# DSS_DSS_COMMON1_30201000h register map
Vendor: Texas Instruments
Peripheral module from a debugger description file (folder am62L).
Registers are 32-bit, access not given, reset 0x0 unless marked. A register's access mark holds for its fields unless they carry their own. Offsets are as the file gives them; lines under a group give offsets from that group; [hi:lo] are bit positions; {n}, {i} and the like mark numbered series; 'fields as' and 'values as' point back to an identical list; <NAME> marks a mode.

## DSS_COMMON1
0x24 DSS_COMMON1_DISPC_IRQ_EOI wo — End Of Interrupt number
  [0] EOI — Software End Of Interrupt [EOI] control if pulse interrupts are used. Write 1 to acknowledge interrupt 0 Write-0 : No action1 Write-1 : End-of-Interrupt
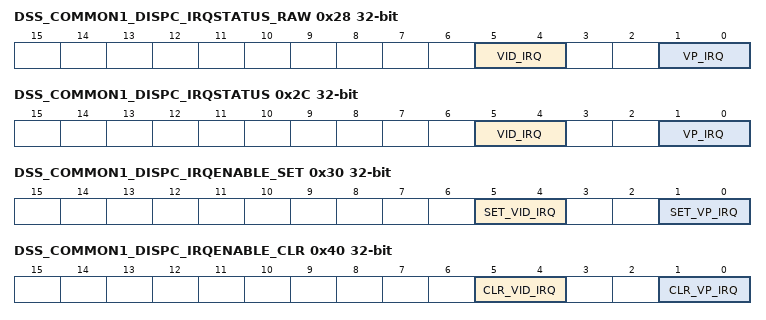
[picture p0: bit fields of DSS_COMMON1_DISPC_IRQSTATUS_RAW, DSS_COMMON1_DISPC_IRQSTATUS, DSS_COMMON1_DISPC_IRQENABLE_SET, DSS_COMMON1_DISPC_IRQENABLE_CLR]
0x28 DSS_COMMON1_DISPC_IRQSTATUS_RAW — RAW Interrupt status. Raw status is set even if interrupt is not enabled. Write 1 to set the RAW status
  [5:4] VID_IRQ — Bit[4]: Reserved, Should be written with 0; Bit[5]:Register indicates the VIDL1 interrupt events ; 0 Write-0 : No action, Read-0 : No event pending1 Write-1 : Set event, Read-1 : IRQ event pending (access R/W1TS)
  [1:0] VP_IRQ — Bit[0]: VP1 IRQ STATUS; Bit[1]: Reserved, Should be written with 0; 0 Write-0 : No action, Read-0 : No event pending1 Write-1 : Set event, Read-1 : IRQ event pending (access R/W1TS)
0x2C DSS_COMMON1_DISPC_IRQSTATUS — Interrupt status. Enabled status, isn't set unless event is enabled. Write 1 to clear the status after interrupt has been serviced. RAW status also gets cleared, i.e. even if not enabled
  [5:4] VID_IRQ — Bit[4]: Reserved, Should be written with 0; Bit[5]:VIDL1 IRQ STATUS; 0 Write-0 : No action, Read-0 : No event pending1 Write-1 : Clear pending event, if any, Read-1 : IRQ event pending (access R/W1TC)
  [1:0] VP_IRQ — Bit[0]: VP1 IRQ STATUS; Bit[1]: Reserved, Should be written with 0; 0 Write-0 : No action, Read-0 : No event pending1 Write-1 : Clear pending event, if any, Read-1 : IRQ event pending (access R/W1TC)
0x30 DSS_COMMON1_DISPC_IRQENABLE_SET — SET Interrupt enable. Write 1 to set interrupt enable. Readout equal to corresponding _CLR register
  [5:4] SET_VID_IRQ — Bit[4]: Reserved, Should be written with 0; Bit[5]:VIDL1 IRQ ; 0 Write-0 : No action, Read-0 : Interrupt Disabled1 Write-1 : Enable interrupt, Read-1 : Interrupt Enabled (access R/W1TS)
  [1:0] SET_VP_IRQ — Bit[0]: VP1 IRQ ; Bit[1]: Reserved, Should be written with 0; 0 Write-0 : No action, Read-0 : Interrupt Disabled1 Write-1 : Enable interrupt, Read-1 : Interrupt Enabled (access R/W1TS)
0x40 DSS_COMMON1_DISPC_IRQENABLE_CLR — CLR Interrupt enable. Write 1 to clear interrupt enable
  [5:4] CLR_VID_IRQ — Bit[4]: Reserved, Should be written with 0; Bit[5]:VIDL1 IRQ ; 0 Write-0 : No action, Read-0 : Interrupt Disabled1 Write-1 : Clear interrupt, Read-1 : Interrupt Enabled (access R/W1TC)
  [1:0] CLR_VP_IRQ — Bit[0]: VP1 IRQ ; Bit[1]: Reserved, Should be written with 0; 0 Write-0 : No action, Read-0 : Interrupt Disabled1 Write-1 : Clear interrupt, Read-1 : Interrupt Enabled (access R/W1TC)
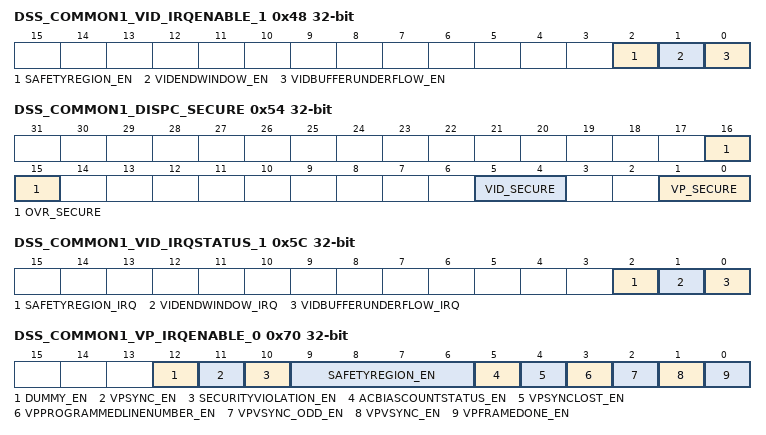
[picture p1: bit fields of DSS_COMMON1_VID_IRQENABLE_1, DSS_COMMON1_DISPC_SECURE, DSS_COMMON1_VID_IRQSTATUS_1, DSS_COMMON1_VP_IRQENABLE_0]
0x48 DSS_COMMON1_VID_IRQENABLE_1 rw — This register allows to mask/unmask the VIDL1 internal sources of interrupt, on an event-by-event basis
  [2] SAFETYREGION_EN — Safety Feature IRQ. This is raised when FrameFreeze is detected or data mismatch occurs within the safety region 0 Event is masked1 Event generates an interrupt when it occurs
  [1] VIDENDWINDOW_EN — Video End Window. This is raised by the DMA engine when the full video data has been sent to the pipeline 0 Event is masked1 Event generates an interrupt when it occurs
  [0] VIDBUFFERUNDERFLOW_EN — Video DMA Buffer Underflow. This is raised when the DMA buffer does not have the data requested by the Video pipeline 0 Event is masked1 Event generates an interrupt when it occurs
0x54 DSS_COMMON1_DISPC_SECURE rw — Security bit settings for different DISPC sub-modules
  [16:15] OVR_SECURE — Secure bit for OVR 0 Secure bit is reset1 Secure bit is set
  [5:4] VID_SECURE — Bit[4]: Reserved , Should be written 0; Bit[5]:Secure bit for VIDL1; 0 Secure bit is reset1 Secure bit is set
  [1:0] VP_SECURE — Bit[0]:Secure bit for VP1; Bit[1]:Reserved, Should be written with 0; 0 Secure bit is reset1 Secure bit is set
0x5C DSS_COMMON1_VID_IRQSTATUS_1 — This register groups all the status of the VIDL1 internal events that generate an interrupt. Write 1 to a clear a bit field
  [2] SAFETYREGION_IRQ — Safety Feature IRQ. This is raised when FrameFreeze is detected or data mismatch occurs within the safety region 0 Write: Status is unchanged, Read: Event is not pending1 Write: Status is reset, Read: Event is Pending (access R/W1TC)
  [1] VIDENDWINDOW_IRQ — Video End Window. This is raised by the DMA engine when the full video data has been sent to the pipeline 0 Write: Status is unchanged, Read: Event is not pending1 Write: Status is reset, Read: Event is Pending (access R/W1TC)
  [0] VIDBUFFERUNDERFLOW_IRQ — Video DMA Buffer Underflow. This is raised when the DMA buffer does not have the data requested by the Video pipeline 0 Write: Status is unchanged, Read: Event is not pending1 Write: Status is reset, Read: Event is Pending (access R/W1TC)
0x70 DSS_COMMON1_VP_IRQENABLE_0 rw — This register allows to mask/unmask the VP_1 internal sources of interrupt, on an event-by-event basis
  [12] DUMMY_EN — Dummy IRQ for future use, in DSS_nano it should always be masked 0 Event is masked1 Event generates an interrupt when it occurs
  [11] VPSYNC_EN — Go bit clear event 0 Event is masked1 Event generates an interrupt when it occurs
  [10] SECURITYVIOLATION_EN — Security Violation interrupt for OVR/VP1. Non-secure OVR/VP1 connected to secure VID 0 Event is masked1 Event generates an interrupt when it occurs
  [9:6] SAFETYREGION_EN — Safety Feature IRQ. This is raised when FrameFreeze is detected or data mismatch occurs within the safety region 0 Event is masked1 Event generates an interrupt when it occurs
  [5] ACBIASCOUNTSTATUS_EN — AC BIAS transition counter has decremented to zero 0 Event is masked1 Event generates an interrupt when it occurs
  [4] VPSYNCLOST_EN — Synchronization Lost for Video Port 0 Event is masked1 Event generates an interrupt when it occurs
  [3] VPPROGRAMMEDLINENUMBER_EN — Programmed Line Number. It indicates that the scan of the display has reached the programmed user line number 0 Event is masked1 Event generates an interrupt when it occurs
  [2] VPVSYNC_ODD_EN — VSYNC for odd field from interlace mode only 0 Event is masked1 Event generates an interrupt when it occurs
  [1] VPVSYNC_EN — Vertical Synchronization for VP1 0 Event is masked1 Event generates an interrupt when it occurs
  [0] VPFRAMEDONE_EN — Frame Done for Video Port. VP1 output has been disabled by user. All the data have been sent 0 Event is masked1 Event generates an interrupt when it occurs
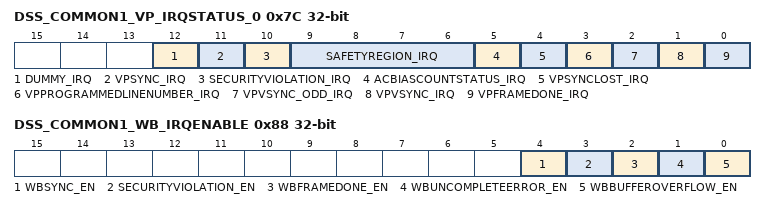
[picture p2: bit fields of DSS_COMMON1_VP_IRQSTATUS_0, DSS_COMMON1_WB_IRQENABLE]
0x7C DSS_COMMON1_VP_IRQSTATUS_0 — This register groups all the status of the VP_1 internal events that generate an interrupt. Write 1 to a given bit resets this bit
  [12] DUMMY_IRQ — Dummy IRQ for future use 0 Write: Status is unchanged, Read: Event is not pending1 Write: Status is reset, Read: Event is Pending (access R/W1TC)
  [11] VPSYNC_IRQ — Go bit clear event 0 Write: Status is unchanged, Read: Event is not pending1 Write: Status is reset, Read: Event is Pending (access R/W1TC)
  [10] SECURITYVIOLATION_IRQ — Security Violation IRQ. Non-secure OVR/VP1 connected to secure VID 0 Write: Status is unchanged, Read: Event is not pending1 Write: Status is reset, Read: Event is Pending (access R/W1TC)
  [9:6] SAFETYREGION_IRQ — Safety Feature IRQ. This is raised when FrameFreeze is detected or data mismatch occurs within the safety region 0 Write: Status is unchanged, Read: Event is not pending1 Write: Status is reset, Read: Event is Pending (access R/W1TC)
  [5] ACBIASCOUNTSTATUS_IRQ — AC BIAS transition counter has decremented to zero 0 Write: Status is unchanged, Read: Event is not pending1 Write: Status is reset, Read: Event is Pending (access R/W1TC)
  [4] VPSYNCLOST_IRQ — Synchronization Lost on VP1 output. The required data are not output at the correct time due to too short blanking periods or stall of at least one pipelines associated with VP1 output 0 Write: Status is unchanged, Read: Event is not pending1 Write: Status is reset, Read: Event is Pending (access R/W1TC)
  [3] VPPROGRAMMEDLINENUMBER_IRQ — Programmed Line Number. It indicates that the scan of the display has reached the programmed user line number 0 Write: Status is unchanged, Read: Event is not pending1 Write: Status is reset, Read: Event is Pending (access R/W1TC)
  [2] VPVSYNC_ODD_IRQ — VSYNC for odd field. For interlace mode only 0 Write: Status is unchanged, Read: Event is not pending1 Write: Status is reset, Read: Event is Pending (access R/W1TC)
  [1] VPVSYNC_IRQ — Vertical Synchronization for VP1 output. It is used as VSYNC_EVEN in case of interlace mode 0 Write: Status is unchanged, Read: Event is not pending1 Write: Status is reset, Read: Event is Pending (access R/W1TC)
  [0] VPFRAMEDONE_IRQ — Frame Done for VP1. VP1 output has been disabled by user All the data have been sent 0 Write: Status is unchanged, Read: Event is not pending1 Write: Status is reset, Read: Event is Pending (access R/W1TC)
0x88 DSS_COMMON1_WB_IRQENABLE rw — This register allows to mask/unmask the WB internal sources of interrupt, if WB pipeline is present, on an event-by-event basis
  [4] WBSYNC_EN — Write-back sync IRQ. Configuration copied from shadow to work for WB for next frame 0 Event is masked1 Event generates an interrupt when it occurs
  [3] SECURITYVIOLATION_EN — Security Violation IRQ. Non-secure WB connected to a secure VID/OVR 0 Event is masked1 Event generates an interrupt when it occurs
  [2] WBFRAMEDONE_EN — Write-back Frame Done 0 Event is masked1 Event generates an interrupt when it occurs
  [1] WBUNCOMPLETEERROR_EN — The write back buffer has been flushed before been fully drained. Can only occur in WB Capture Mode use-case 0 Event is masked1 Event generates an interrupt when it occurs
  [0] WBBUFFEROVERFLOW_EN — Write-back DMA Buffer Overflow. Can only occur in WB Capture Mode use-case 0 Event is masked1 Event generates an interrupt when it occurs
